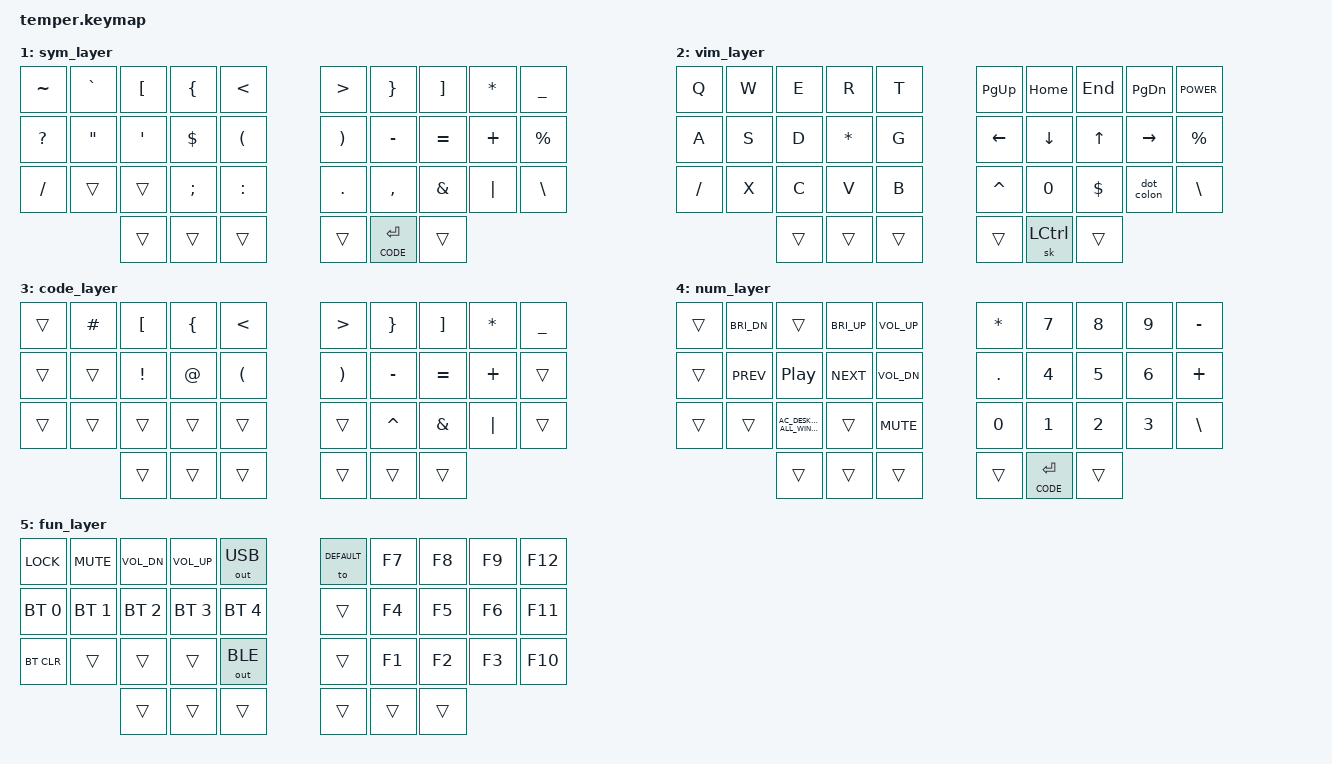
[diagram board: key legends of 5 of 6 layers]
/*
 * Copyright (c) 2020 The ZMK Contributors
 *
 * SPDX-License-Identifier: MIT
 */

#include <behaviors.dtsi>
#include <dt-bindings/zmk/keys.h>
#include <dt-bindings/zmk/bt.h>
#include <dt-bindings/zmk/outputs.h>

// Home row mods
#define HRML(k2,k3,k4) &ht LALT k2  &ht LCTRL k3  &ht LGUI k4
#define HRMR(k1,k2,k3) &ht RGUI k1  &ht RCTRL k2  &ht RALT k3

#define DEFAULT 0
#define SYM 1
#define VIM 2
#define CODE 3
#define NUM 4
#define FUN 5

# define ______ &trans

/ {
    conditional_layers {
        compatible = "zmk,conditional-layers";
        tri_layer {
            if-layers = <CODE VIM>;
            then-layer = <FUN>;
        };
    };
    behaviors {
        // HOME ROW
        ht: hold_tap {
            label = "hold_tap";
            compatible = "zmk,behavior-hold-tap";
            #binding-cells = <2>;
            flavor = "tap-preferred";
            tapping-term-ms = <220>;
            quick-tap-ms = <150>;
            /* global-quick-tap; */
            bindings = <&kp>,<&kp>;
        };
        // THUMB
        lt_nav: lt_nav {
            label = "NAV_BSPC";
            compatible = "zmk,behavior-hold-tap";
            #binding-cells = <2>;
            flavor = "balanced";
            tapping-term-ms = <180>;
            bindings = <&mo>, <&kp>;
        };
       lt_sym: lt_sym {
            label = "SYM_SPC";
            compatible = "zmk,behavior-hold-tap";
            #binding-cells = <2>;
            flavor = "balanced";
            tapping-term-ms = <180>;
            bindings = <&mo>, <&kp>;
        };
       lt_code: lt_code {
            label = "CODE_RET";
            compatible = "zmk,behavior-hold-tap";
            #binding-cells = <2>;
            flavor = "balanced";
            tapping-term-ms = <180>;
            bindings = <&mo>, <&kp>;
        };
       lt_num: lt_num {
            label = "NUM_TAB";
            compatible = "zmk,behavior-hold-tap";
            #binding-cells = <2>;
            flavor = "balanced";
            tapping-term-ms = <180>;
            bindings = <&mo>, <&kp>;
        };
        bspc_del: backspace_delete {
            compatible = "zmk,behavior-mod-morph";
            #binding-cells = <0>;
            bindings = <&kp BACKSPACE>, <&kp DELETE>;
            mods = <(MOD_LSFT|MOD_RSFT)>;
            keep-mods = <(MOD_RSFT)>;
        };
        /* super_bspc: super_backspace { */
        /*     compatible = "zmk,behavior-mod-morph"; */
        /*     #binding-cells = <0>; */
        /*     bindings = <&kp BACKSPACE>, <&kp LA(BACKSPACE)>; */
        /*     mods = <(MOD_LSFT|MOD_RSFT)>; */
        /* }; */
        smart_shft: smart_shift {
            compatible = "zmk,behavior-mod-morph";
            #binding-cells = <0>;
            bindings = <&kp LSHFT>, <&caps_word>;
            mods = <(MOD_LSFT)>;
        };
        comma_semi: comma_semi {
            compatible = "zmk,behavior-mod-morph";
            #binding-cells = <0>;
            bindings = <&kp COMMA>, <&kp SEMI>;
            mods = <(MOD_LSFT)>;
        };
        dot_colon: dot_colon {
            compatible = "zmk,behavior-mod-morph";
            #binding-cells = <0>;
            bindings = <&kp DOT>, <&kp COLON>;
            mods = <(MOD_LSFT)>;
        };
        eql_excl: eql_excl {
            compatible = "zmk,behavior-mod-morph";
            #binding-cells = <0>;
            bindings = <&kp EQUAL>, <&kp EXCL>;
            mods = <(MOD_LSFT)>;
        };
        /* slh_morph: slh_morph { */
        /*     compatible = "zmk,behavior-mod-morph"; */
        /*     #binding-cells = <0>; */
        /*     bindings = <&kp FSLH>, <&kp BSLH>; */
        /*     mods = <(MOD_LSFT)>; */
        /* }; */
        /* amps_morph: amps_morph { */
        /*     compatible = "zmk,behavior-mod-morph"; */
        /*     #binding-cells = <0>; */
        /*     bindings = <&kp AMPS>, <&kp PIPE>; */
        /*     mods = <(MOD_LSFT)>; */
        /* }; */
        /* tilde_morph: tilde_morph { */
        /*     compatible = "zmk,behavior-mod-morph"; */
        /*     #binding-cells = <0>; */
        /*     bindings = <&kp TILDE>, <&kp GRAVE>; */
        /*     mods = <(MOD_LSFT)>; */
        /* }; */
    };
        keymap {
                compatible = "zmk,keymap";

                default_layer {
                        bindings = <
// ╭─────────────┬─────────────┬─────────────┬─────────────┬─────────────╮   ╭─────────────┬─────────────┬─────────────┬─────────────┬─────────────╮
        &kp Q         &kp W         &kp E         &kp R         &kp T             &kp Y         &kp U         &kp I         &kp O         &kp P
// ├─────────────┼─────────────┼─────────────┼─────────────┼─────────────┤   ├─────────────┼─────────────┼─────────────┼─────────────┼─────────────┤
//      &kp A         &kp S         &kp D         &kp F         &kp G             &kp H         &kp J         &kp K         &kp L       &kp APOS
	&kp A        HRML(S,            D,            F)        &kp G             &kp H       HRMR(J,             K,            L)      &kp APOS
// ├─────────────┼─────────────┼─────────────┼─────────────┼─────────────┤   ├─────────────┼─────────────┼─────────────┼─────────────┼─────────────┤
        &kp Z         &kp X         &kp C         &kp V         &kp B             &kp N         &kp M      &comma_semi    &dot_colon    &eql_excl
// ╰─────────────┴─────────────┼─────────────┼─────────────┼─────────────┤   ├─────────────┼─────────────┼─────────────┼─────────────┴─────────────╯
                               &gresc  &lt_nav VIM BACKSPACE &lt_num NUM TAB &lt_sym SYM SPACE &lt_code CODE RET  &smart_shft
//                             ╰─────────────┴─────────────┴─────────────╯   ╰─────────────┴─────────────┴─────────────╯
                        >;
                };
                sym_layer {
                        bindings = <
// ╭─────────────┬─────────────┬─────────────┬─────────────┬─────────────╮   ╭─────────────┬─────────────┬─────────────┬─────────────┬─────────────╮
     &kp TILDE      &kp GRAVE     &kp LBKT     &kp LBRC       &kp LT             &kp GT        &kp RBRC      &kp RBKT      &kp STAR     &kp UNDER
// ├─────────────┼─────────────┼─────────────┼─────────────┼─────────────┤   ├─────────────┼─────────────┼─────────────┼─────────────┼─────────────┤
     &kp QMARK       &kp DQT      &kp SQT       &kp DLLR      &kp LPAR           &kp RPAR      &kp MINUS     &kp EQUAL     &kp PLUS     &kp PRCNT
// ├─────────────┼─────────────┼─────────────┼─────────────┼─────────────┤   ├─────────────┼─────────────┼─────────────┼─────────────┼─────────────┤
     &kp FSLH       ______         ______       &kp SEMI      &kp COLON          &kp DOT       &kp COMMA     &kp AMPS      &kp PIPE     &kp BSLH
// ╰─────────────┴─────────────┼─────────────┼─────────────┼─────────────┤   ├─────────────┼─────────────┼─────────────┼─────────────┴─────────────╯
                                   ______         ______        ______            ______  &lt_code CODE RET   ______
//                             ╰─────────────┴─────────────┴─────────────╯   ╰─────────────┴─────────────┴─────────────╯
                        >;
                };

               vim_layer {
                        bindings = <
// ╭─────────────┬─────────────┬─────────────┬─────────────┬─────────────╮   ╭─────────────┬─────────────┬─────────────┬─────────────┬─────────────╮
      &kp Q          &kp W        &kp E          &kp R          &kp T            &kp PG_UP     &kp HOME      &kp END      &kp PG_DN     &kp C_POWER
// ├─────────────┼─────────────┼─────────────┼─────────────┼─────────────┤   ├─────────────┼─────────────┼─────────────┼─────────────┼─────────────┤
      &kp A          &kp S         &kp D         &kp STAR       &kp G            &kp LEFT      &kp DOWN      &kp UP       &kp RIGHT     &kp PRCNT
// ├─────────────┼─────────────┼─────────────┼─────────────┼─────────────┤   ├─────────────┼─────────────┼─────────────┼─────────────┼─────────────┤
      &kp FSLH       &kp X         &kp C         &kp V          &kp B            &kp CARET     &kp N0        &kp DLLR     &dot_colon    &kp BSLH
// ╰─────────────┴─────────────┼─────────────┼─────────────┼─────────────┤   ├─────────────┼─────────────┼─────────────┼─────────────┴─────────────╯
                                    ______        ______        ______            ______       &sk LCTRL     ______
//                             ╰─────────────┴─────────────┴─────────────╯   ╰─────────────┴─────────────┴─────────────╯
                        >;
                };

                code_layer {
                        bindings = <
// ╭─────────────┬─────────────┬─────────────┬─────────────┬─────────────╮   ╭─────────────┬─────────────┬─────────────┬─────────────┬─────────────╮
        ______       &kp HASH      &kp LBKT      &kp LBRC      &kp LT            &kp GT        &kp RBRC      &kp RBKT       &kp STAR     &kp UNDER
// ├─────────────┼─────────────┼─────────────┼─────────────┼─────────────┤   ├─────────────┼─────────────┼─────────────┼─────────────┼─────────────┤
        ______         ______      &kp EXCL      &kp AT        &kp LPAR          &kp RPAR      &kp MINUS     &kp EQUAL      &kp PLUS     ______
// ├─────────────┼─────────────┼─────────────┼─────────────┼─────────────┤   ├─────────────┼─────────────┼─────────────┼─────────────┼─────────────┤
        ______         ______      ______        ______        ______            ______        &kp CARET     &kp AMPS       &kp PIPE     ______
// ╰─────────────┴─────────────┼─────────────┼─────────────┼─────────────┤   ├─────────────┼─────────────┼─────────────┼─────────────┴─────────────╯
                                   ______         ______       ______            ______        ______         ______
//                             ╰─────────────┴─────────────┴─────────────╯   ╰─────────────┴─────────────┴─────────────╯
                        >;
                };

                num_layer {
                        bindings = <
// ╭─────────────┬─────────────┬─────────────┬─────────────┬─────────────╮   ╭─────────────┬─────────────┬─────────────┬─────────────┬─────────────╮
        ______     &kp C_BRI_DN      ______   &kp C_BRI_UP   &kp C_VOL_UP         &kp STAR       &kp N7        &kp N8        &kp N9      &kp MINUS
// ├─────────────┼─────────────┼─────────────┼─────────────┼─────────────┤   ├─────────────┼─────────────┼─────────────┼─────────────┼─────────────┤
        ______     &kp C_PREV      &kp C_PP     &kp C_NEXT   &kp C_VOL_DN         &kp DOT        &kp N4        &kp N5        &kp N6      &kp PLUS
// ├─────────────┼─────────────┼─────────────┼─────────────┼─────────────┤   ├─────────────┼─────────────┼─────────────┼─────────────┼─────────────┤
    ______ ______ &kp C_AC_DESKTOP_SHOW_ALL_WINDOWS ______   &kp K_MUTE           &kp N0         &kp N1        &kp N2        &kp N3      &kp BSLH
// ╰─────────────┴─────────────┼─────────────┼─────────────┼─────────────┤   ├─────────────┼─────────────┼─────────────┼─────────────┴─────────────╯
                                     ______       ______        ______            ______  &lt_code CODE RET   ______
//                             ╰─────────────┴─────────────┴─────────────╯   ╰─────────────┴─────────────┴─────────────╯
                        >;
                };

                fun_layer {
                        bindings = <
// ╭─────────────┬─────────────┬─────────────┬─────────────┬─────────────╮   ╭─────────────┬─────────────┬─────────────┬─────────────┬─────────────╮
      &kp K_LOCK   &kp K_MUTE    &kp C_VOL_DN  &kp C_VOL_UP  &out OUT_USB      &to DEFAULT      &kp F7        &kp F8        &kp F9       &kp F12
// ├─────────────┼─────────────┼─────────────┼─────────────┼─────────────┤   ├─────────────┼─────────────┼─────────────┼─────────────┼─────────────┤
     &bt BT_SEL 0  &bt BT_SEL 1  &bt BT_SEL 2  &bt BT_SEL 3  &bt BT_SEL 4         ______        &kp F4        &kp F5        &kp F6       &kp F11
// ├─────────────┼─────────────┼─────────────┼─────────────┼─────────────┤   ├─────────────┼─────────────┼─────────────┼─────────────┼─────────────┤
      &bt BT_CLR     ______        ______        ______      &out OUT_BLE         ______        &kp F1        &kp F2        &kp F3       &kp F10
// ╰─────────────┴─────────────┼─────────────┼─────────────┼─────────────┤   ├─────────────┼─────────────┼─────────────┼─────────────┴─────────────╯
                                    ______        ______        ______            ______        ______        ______
//                             ╰─────────────┴─────────────┴─────────────╯   ╰─────────────┴─────────────┴─────────────╯
                        >;
                };

        };
};
